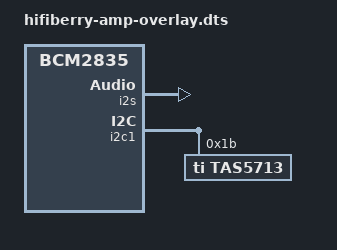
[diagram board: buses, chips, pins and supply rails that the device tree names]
// Definitions for HiFiBerry Amp/Amp+
/dts-v1/;
/plugin/;

/ {
	compatible = "brcm,bcm2835";

	fragment@0 {
		target = <&i2s>;
		__overlay__ {
			status = "okay";
		};
	};

	fragment@1 {
		target = <&i2c1>;
		__overlay__ {
			#address-cells = <1>;
			#size-cells = <0>;
			status = "okay";

			tas5713@1b {
				#sound-dai-cells = <0>;
				compatible = "ti,tas5713";
				reg = <0x1b>;
				status = "okay";
			};
		};
	};

	fragment@2 {
		target = <&sound>;
		__overlay__ {
			compatible = "hifiberry,hifiberry-amp";
			i2s-controller = <&i2s>;
			status = "okay";
		};
	};
};
